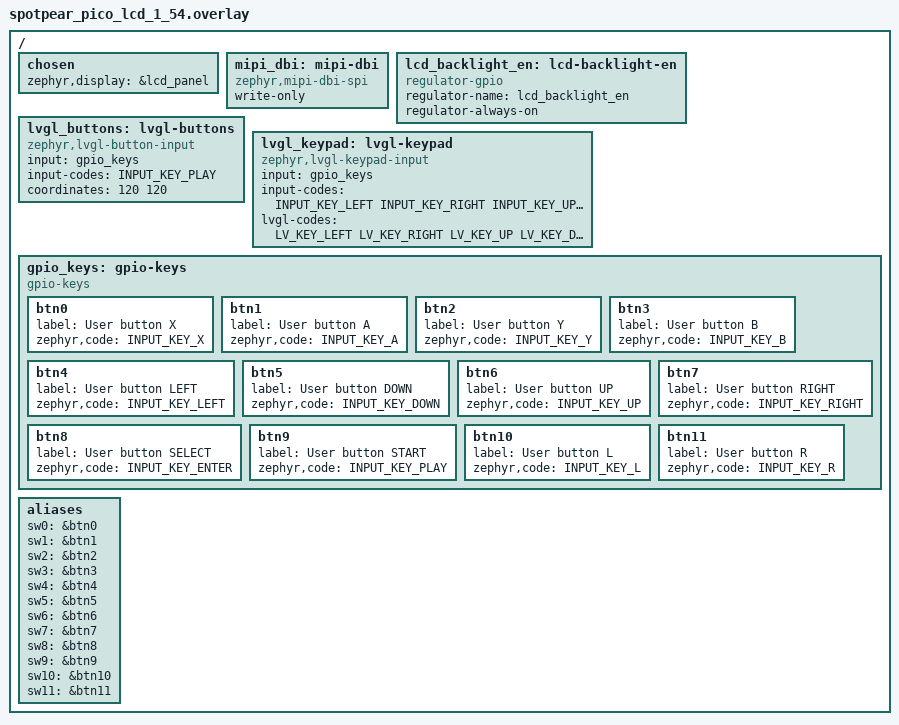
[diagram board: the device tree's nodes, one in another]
/*
 * SPDX-FileCopyrightText: Copyright (c) 2024-2026 TiaC Systems
 * SPDX-License-Identifier: Apache-2.0
 */

#include <zephyr/dt-bindings/input/input-event-codes.h>
#include <zephyr/dt-bindings/lvgl/lvgl.h>

/ {
	chosen {
		zephyr,display = &lcd_panel;
	};

	mipi_dbi: mipi-dbi {
		compatible = "zephyr,mipi-dbi-spi";
		write-only;
	};

	lcd_backlight_en: lcd-backlight-en {
		compatible = "regulator-gpio";
		regulator-name = "lcd_backlight_en";
		regulator-always-on;
	};

	lvgl_buttons: lvgl-buttons {
		compatible = "zephyr,lvgl-button-input";
		input = <&gpio_keys>;
		input-codes = <INPUT_KEY_PLAY>;
		coordinates = <120 120>;
	};

	lvgl_keypad: lvgl-keypad {
		compatible = "zephyr,lvgl-keypad-input";
		input = <&gpio_keys>;
		input-codes = <INPUT_KEY_LEFT INPUT_KEY_RIGHT
			       INPUT_KEY_UP INPUT_KEY_DOWN
			       INPUT_KEY_ENTER>;
		lvgl-codes = <LV_KEY_LEFT LV_KEY_RIGHT
			      LV_KEY_UP LV_KEY_DOWN
			      LV_KEY_ENTER>;
	};

	/delete-node/ gpio_keys;
	/delete-node/ gpio-keys;
	gpio_keys: gpio-keys {
		compatible = "gpio-keys";
		btn0: btn0 {
			label = "User button X";
			zephyr,code = <INPUT_KEY_X>;
		};
		btn1: btn1 {
			label = "User button A";
			zephyr,code = <INPUT_KEY_A>;
		};
		btn2: btn2 {
			label = "User button Y";
			zephyr,code = <INPUT_KEY_Y>;
		};
		btn3: btn3 {
			label = "User button B";
			zephyr,code = <INPUT_KEY_B>;
		};
		btn4: btn4 {
			label = "User button LEFT";
			zephyr,code = <INPUT_KEY_LEFT>;
		};
		btn5: btn5 {
			label = "User button DOWN";
			zephyr,code = <INPUT_KEY_DOWN>;
		};
		btn6: btn6 {
			label = "User button UP";
			zephyr,code = <INPUT_KEY_UP>;
		};
		btn7: btn7 {
			label = "User button RIGHT";
			zephyr,code = <INPUT_KEY_RIGHT>;
		};
		btn8: btn8 {
			label = "User button SELECT";
			zephyr,code = <INPUT_KEY_ENTER>;
		};
		btn9: btn9 {
			label = "User button START";
			zephyr,code = <INPUT_KEY_PLAY>;
		};
		btn10: btn10 {
			label = "User button L";
			zephyr,code = <INPUT_KEY_L>;
		};
		btn11: btn11 {
			label = "User button R";
			zephyr,code = <INPUT_KEY_R>;
		};
	};

	aliases {
		/delete-property/ sw0;
		sw0 = &btn0;
		sw1 = &btn1;
		sw2 = &btn2;
		sw3 = &btn3;
		sw4 = &btn4;
		sw5 = &btn5;
		sw6 = &btn6;
		sw7 = &btn7;
		sw8 = &btn8;
		sw9 = &btn9;
		sw10 = &btn10;
		sw11 = &btn11;
	};
};
